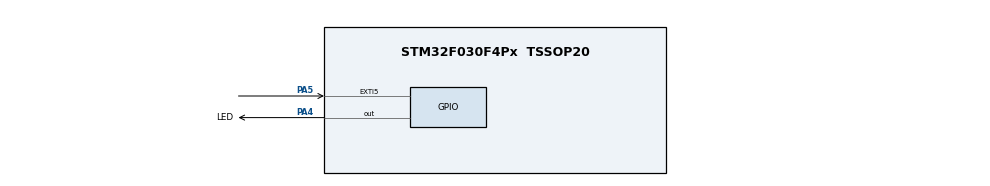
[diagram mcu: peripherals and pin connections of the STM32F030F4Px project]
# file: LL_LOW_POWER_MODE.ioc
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Mcu.Family=STM32F0
Mcu.Name=STM32F030F4Px
Mcu.Package=TSSOP20
NVIC.EXTI4_15_IRQn=true\:1\:0\:true\:true\:true\:1\:true
PA0.Mode=SYS_WakeUp0
PA0.Signal=SYS_WKUP1
PA13.Mode=Serial_Wire
PA13.Signal=SYS_SWDIO
PA14.Mode=Serial_Wire
PA14.Signal=SYS_SWCLK
PA4.GPIO_Label=LED
PA4.Signal=GPIO_Output
PA5.GPIO_ModeDefaultEXTI=GPIO_MODE_IT_RISING
PA5.Signal=GPXTI5
PF0-OSC_IN.Mode=HSE-External-Oscillator
PF0-OSC_IN.Signal=RCC_OSC_IN
PF1-OSC_OUT.Mode=HSE-External-Oscillator
PF1-OSC_OUT.Signal=RCC_OSC_OUT
ProjectManager.HeapSize=0x200
ProjectManager.StackSize=0x400
ProjectManager.TargetToolchain=EWARM
RCC.AHBFreq_Value=48000000
RCC.APB1Freq_Value=48000000
RCC.APB1TimFreq_Value=48000000
RCC.HCLKFreq_Value=48000000
RCC.PLLMUL=RCC_PLL_MUL12
RCC.SYSCLKFreq_VALUE=48000000
RCC.SYSCLKSource=RCC_SYSCLKSOURCE_PLLCLK
board=LL_LOW_POWER_MODE

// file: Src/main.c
/**
  ******************************************************************************
  * File Name          : main.c
  * Description        : Main program body
  ******************************************************************************
  ** This notice applies to any and all portions of this file
  * that are not between comment pairs USER CODE BEGIN and
  * USER CODE END. Other portions of this file, whether
  * inserted by the user or by software development tools
  * are owned by their respective copyright owners.
  *
  * COPYRIGHT(c) 2018 STMicroelectronics
  *
  * Redistribution and use in source and binary forms, with or without modification,
  * are permitted provided that the following conditions are met:
  *   1. Redistributions of source code must retain the above copyright notice,
  *      this list of conditions and the following disclaimer.
  *   2. Redistributions in binary form must reproduce the above copyright notice,
  *      this list of conditions and the following disclaimer in the documentation
  *      and/or other materials provided with the distribution.
  *   3. Neither the name of STMicroelectronics nor the names of its contributors
  *      may be used to endorse or promote products derived from this software
  *      without specific prior written permission.
  *
  * THIS SOFTWARE IS PROVIDED BY THE COPYRIGHT HOLDERS AND CONTRIBUTORS "AS IS"
  * AND ANY EXPRESS OR IMPLIED WARRANTIES, INCLUDING, BUT NOT LIMITED TO, THE
  * IMPLIED WARRANTIES OF MERCHANTABILITY AND FITNESS FOR A PARTICULAR PURPOSE ARE
  * DISCLAIMED. IN NO EVENT SHALL THE COPYRIGHT HOLDER OR CONTRIBUTORS BE LIABLE
  * FOR ANY DIRECT, INDIRECT, INCIDENTAL, SPECIAL, EXEMPLARY, OR CONSEQUENTIAL
  * DAMAGES (INCLUDING, BUT NOT LIMITED TO, PROCUREMENT OF SUBSTITUTE GOODS OR
  * SERVICES; LOSS OF USE, DATA, OR PROFITS; OR BUSINESS INTERRUPTION) HOWEVER
  * CAUSED AND ON ANY THEORY OF LIABILITY, WHETHER IN CONTRACT, STRICT LIABILITY,
  * OR TORT (INCLUDING NEGLIGENCE OR OTHERWISE) ARISING IN ANY WAY OUT OF THE USE
  * OF THIS SOFTWARE, EVEN IF ADVISED OF THE POSSIBILITY OF SUCH DAMAGE.
  *
  ******************************************************************************
  */

#include "main.h"

/* USER CODE BEGIN PV */
/* Private variables ---------------------------------------------------------*/

/* USER CODE END PV */

static void LL_Init(void);
void SystemClock_Config(void);
static void MX_GPIO_Init(void);
static void MX_NVIC_Init(void);

/* USER CODE BEGIN PFP */
/* Private function prototypes -----------------------------------------------*/
void EnterStandbyMode(void);
void EnterSTOP_LPREGUMode(void);
/* USER CODE END PFP */

int main(void)
{

  /* MCU Configuration----------------------------------------------------------*/

  /* Reset of all peripherals, Initializes the Flash interface and the Systick. */
  LL_Init();

  /* Configure the system clock */
  SystemClock_Config();

  /* Initialize all configured peripherals */
  MX_GPIO_Init();

  /* Initialize interrupts */
  MX_NVIC_Init();

  /* Infinite loop */
  while (1)
  {

  /* USER CODE BEGIN 3 */
    LL_GPIO_TogglePin(LED_GPIO_Port, LED_Pin);
    LL_mDelay(100);
  }
  /* USER CODE END 3 */

}

static void LL_Init(void)
{

  LL_APB1_GRP2_EnableClock(LL_APB1_GRP2_PERIPH_SYSCFG);

  /* System interrupt init*/
  /* SVC_IRQn interrupt configuration */
  NVIC_SetPriority(SVC_IRQn, 0);
  /* PendSV_IRQn interrupt configuration */
  NVIC_SetPriority(PendSV_IRQn, 0);
  /* SysTick_IRQn interrupt configuration */
  NVIC_SetPriority(SysTick_IRQn, 0);

}

/** System Clock Configuration
*/
void SystemClock_Config(void)
{

  LL_FLASH_SetLatency(LL_FLASH_LATENCY_1);

  if(LL_FLASH_GetLatency() != LL_FLASH_LATENCY_1)
  {
  Error_Handler();
  }
  LL_RCC_HSI_Enable();

   /* Wait till HSI is ready */
  while(LL_RCC_HSI_IsReady() != 1)
  {

  }
  LL_RCC_HSI_SetCalibTrimming(16);

  LL_RCC_PLL_ConfigDomain_SYS(LL_RCC_PLLSOURCE_HSI_DIV_2, LL_RCC_PLL_MUL_12);

  LL_RCC_PLL_Enable();

   /* Wait till PLL is ready */
  while(LL_RCC_PLL_IsReady() != 1)
  {

  }
  LL_RCC_SetAHBPrescaler(LL_RCC_SYSCLK_DIV_1);

  LL_RCC_SetAPB1Prescaler(LL_RCC_APB1_DIV_1);

  LL_RCC_SetSysClkSource(LL_RCC_SYS_CLKSOURCE_PLL);

   /* Wait till System clock is ready */
  while(LL_RCC_GetSysClkSource() != LL_RCC_SYS_CLKSOURCE_STATUS_PLL)
  {

  }
  LL_Init1msTick(48000000);

  LL_SYSTICK_SetClkSource(LL_SYSTICK_CLKSOURCE_HCLK);

  LL_SetSystemCoreClock(48000000);

  /* SysTick_IRQn interrupt configuration */
  NVIC_SetPriority(SysTick_IRQn, 0);
}

/** NVIC Configuration
*/
static void MX_NVIC_Init(void)
{
  /* EXTI4_15_IRQn interrupt configuration */
  NVIC_SetPriority(EXTI4_15_IRQn, 1);
  NVIC_EnableIRQ(EXTI4_15_IRQn);
}

/** Configure pins as
        * Analog
        * Input
        * Output
        * EVENT_OUT
        * EXTI
*/
static void MX_GPIO_Init(void)
{

  LL_GPIO_InitTypeDef GPIO_InitStruct;
  LL_EXTI_InitTypeDef EXTI_InitStruct;

  /* GPIO Ports Clock Enable */
  LL_AHB1_GRP1_EnableClock(LL_AHB1_GRP1_PERIPH_GPIOF);
  LL_AHB1_GRP1_EnableClock(LL_AHB1_GRP1_PERIPH_GPIOA);

  /**/
  LL_GPIO_ResetOutputPin(LED_GPIO_Port, LED_Pin);

  /**/
  GPIO_InitStruct.Pin = LED_Pin;
  GPIO_InitStruct.Mode = LL_GPIO_MODE_OUTPUT;
  GPIO_InitStruct.Speed = LL_GPIO_SPEED_FREQ_LOW;
  GPIO_InitStruct.OutputType = LL_GPIO_OUTPUT_PUSHPULL;
  GPIO_InitStruct.Pull = LL_GPIO_PULL_NO;
  LL_GPIO_Init(LED_GPIO_Port, &GPIO_InitStruct);

  /**/
  LL_SYSCFG_SetEXTISource(LL_SYSCFG_EXTI_PORTA, LL_SYSCFG_EXTI_LINE5);

  /**/
  LL_GPIO_SetPinPull(GPIOA, LL_GPIO_PIN_5, LL_GPIO_PULL_NO);

  /**/
  LL_GPIO_SetPinMode(GPIOA, LL_GPIO_PIN_5, LL_GPIO_MODE_INPUT);

  /**/
  EXTI_InitStruct.Line_0_31 = LL_EXTI_LINE_5;
  EXTI_InitStruct.LineCommand = ENABLE;
  EXTI_InitStruct.Mode = LL_EXTI_MODE_IT;
  EXTI_InitStruct.Trigger = LL_EXTI_TRIGGER_RISING;
  LL_EXTI_Init(&EXTI_InitStruct);

}

/* USER CODE BEGIN 4 */
void EnterStandbyMode(void)
{
  /* Disable all used wakeup sources */
  LL_PWR_DisableWakeUpPin(LL_PWR_WAKEUP_PIN1);
  /* Clear all wake up Flag */
  LL_PWR_ClearFlag_WU();
  /* Enable wakeup pin */
  LL_PWR_EnableWakeUpPin(LL_PWR_WAKEUP_PIN1);
  /** Request to enter STANDBY mode
    * Following procedure describe in STM32F0xx Reference Manual
    * See PWR part, section Low-power modes, Standby mode
    */
  /* Set STANDBY mode when CPU enters deepsleep */
  LL_PWR_SetPowerMode(LL_PWR_MODE_STANDBY);
  /* Set SLEEPDEEP bit of Cortex System Control Register */
  LL_LPM_EnableDeepSleep();

  /* Request Wait For Interrupt */
  __WFI();
}
void EnterSTOP_LPREGUMode(void)
{
  //所有的GPIO设置为analog模式，减小电流消耗
  LL_GPIO_InitTypeDef gpio_initstruct = {LL_GPIO_PIN_ALL,
                                         LL_GPIO_MODE_ANALOG,
                                         LL_GPIO_SPEED_FREQ_HIGH,
                                         LL_GPIO_OUTPUT_PUSHPULL,
                                         LL_GPIO_PULL_NO,
                                         LL_GPIO_AF_0};

  LL_AHB1_GRP1_EnableClock(LL_AHB1_GRP1_PERIPH_GPIOA
                           |LL_AHB1_GRP1_PERIPH_GPIOB
                           |LL_AHB1_GRP1_PERIPH_GPIOF);

  LL_GPIO_Init(GPIOA, &gpio_initstruct);
  LL_GPIO_Init(GPIOB, &gpio_initstruct);
  LL_GPIO_Init(GPIOF, &gpio_initstruct);

  LL_AHB1_GRP1_DisableClock(LL_AHB1_GRP1_PERIPH_GPIOA
                            |LL_AHB1_GRP1_PERIPH_GPIOB
                            |LL_AHB1_GRP1_PERIPH_GPIOF);

  /** Request to enter STOP_LPREGU mode
    * Following procedure describe in STM32F0xx Reference Manual
    * See PWR part, section Low-power modes, STOP_LPREGU mode
    */
  /* Set STOP_LPREGU mode when CPU enters deepsleep */
  LL_PWR_SetPowerMode(LL_PWR_MODE_STOP_LPREGU);
  /* Set SLEEPDEEP bit of Cortex System Control Register */
  LL_LPM_EnableDeepSleep();
  /* Request Wait For Interrupt */
  __WFI();
}

void LL_EXTI_LINE_5_CallBack(void)
{
  uint8_t Entry=0;
  uint16_t Count=0;
     LL_mDelay(10);
  if(LL_GPIO_IsInputPinSet(GPIOA,LL_GPIO_PIN_5)==SET)
  {
       for(;Count<3000;Count++)
       {
         LL_mDelay(1);
         if( (LL_GPIO_IsInputPinSet(GPIOA,LL_GPIO_PIN_5)!=SET))
          {Entry=0;Count=0;}
       }

      for(;Count<3000;Count++)
       {
         LL_mDelay(1);
         if( (LL_GPIO_IsInputPinSet(GPIOA,LL_GPIO_PIN_5)!=SET))
          {Entry=1;Count=0;}
         else
          {Entry=3;Count=0;}
       }
       if(Entry==0) EnterStandbyMode();

       if(Entry==1) EnterSTOP_LPREGUMode();

       if(Entry==3)
       {
         for(;Count<5;Count++)
         {
           LL_GPIO_TogglePin(LED_GPIO_Port, LED_Pin);
           LL_mDelay(50);
         }
       }
  }

}
/* USER CODE END 4 */

void _Error_Handler(char * file, int line)
{
  while(1)
  {
  }
}

/************************ (C) COPYRIGHT STMicroelectronics *****END OF FILE****/
